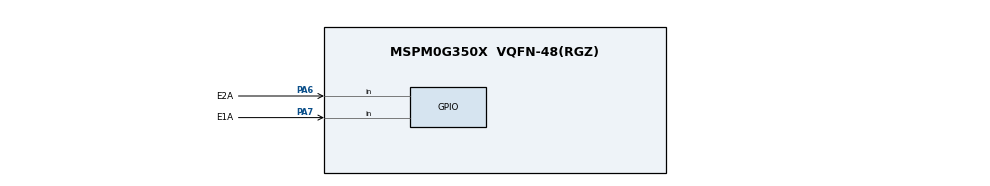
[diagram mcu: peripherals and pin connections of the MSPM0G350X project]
/**
 * @cliArgs --device "MSPM0G350X" --package "VQFN-48(RGZ)" --part "Default" --product "mspm0_sdk@2.00.01.00"
 * @versions {"tool":"1.20.0+3587"}
 */

/**
 * Import the modules used in this configuration.
 */
const Board  = scripting.addModule("/ti/driverlib/Board");
const GPIO   = scripting.addModule("/ti/driverlib/GPIO", {}, false);
const GPIO1  = GPIO.addInstance();
const GPIO2  = GPIO.addInstance();
const I2C    = scripting.addModule("/ti/driverlib/I2C", {}, false);
const I2C1   = I2C.addInstance();
const PWM    = scripting.addModule("/ti/driverlib/PWM", {}, false);
const PWM1   = PWM.addInstance();
const TIMER  = scripting.addModule("/ti/driverlib/TIMER", {}, false);
const TIMER1 = TIMER.addInstance();
const TIMER2 = TIMER.addInstance();

/**
 * Write custom configuration values to the imported modules.
 */

GPIO1.$name                       = "track";
GPIO1.associatedPins.create(8);
GPIO1.associatedPins[0].direction = "INPUT";
GPIO1.associatedPins[0].$name     = "PIN_1";
GPIO1.associatedPins[1].$name     = "PIN_2";
GPIO1.associatedPins[1].direction = "INPUT";
GPIO1.associatedPins[2].$name     = "PIN_3";
GPIO1.associatedPins[2].direction = "INPUT";
GPIO1.associatedPins[3].$name     = "PIN_4";
GPIO1.associatedPins[3].direction = "INPUT";
GPIO1.associatedPins[4].$name     = "PIN_5";
GPIO1.associatedPins[4].direction = "INPUT";
GPIO1.associatedPins[5].$name     = "PIN_6";
GPIO1.associatedPins[5].direction = "INPUT";
GPIO1.associatedPins[6].$name     = "PIN_7";
GPIO1.associatedPins[6].direction = "INPUT";
GPIO1.associatedPins[7].$name     = "PIN_8";
GPIO1.associatedPins[7].direction = "INPUT";

GPIO2.$name                         = "motor";
GPIO2.associatedPins.create(8);
GPIO2.associatedPins[0].$name       = "AIN1";
GPIO2.associatedPins[1].$name       = "AIN2";
GPIO2.associatedPins[2].$name       = "BIN1";
GPIO2.associatedPins[3].$name       = "BIN2";
GPIO2.associatedPins[4].$name       = "E1A";
GPIO2.associatedPins[4].direction   = "INPUT";
GPIO2.associatedPins[4].interruptEn = true;
GPIO2.associatedPins[4].polarity    = "FALL";
GPIO2.associatedPins[4].pin.$assign = "PA7";
GPIO2.associatedPins[5].$name       = "E2A";
GPIO2.associatedPins[5].direction   = "INPUT";
GPIO2.associatedPins[5].interruptEn = true;
GPIO2.associatedPins[5].polarity    = "FALL";
GPIO2.associatedPins[5].pin.$assign = "PA6";
GPIO2.associatedPins[6].$name       = "E1B";
GPIO2.associatedPins[6].direction   = "INPUT";
GPIO2.associatedPins[7].$name       = "E2B";
GPIO2.associatedPins[7].direction   = "INPUT";

I2C1.$name              = "I2C_0";
I2C1.sdaPinConfig.$name = "ti_driverlib_gpio_GPIOPinGeneric0";
I2C1.sclPinConfig.$name = "ti_driverlib_gpio_GPIOPinGeneric1";

PWM1.$name                              = "PWM_motor";
PWM1.timerStartTimer                    = true;
PWM1.clockPrescale                      = 256;
PWM1.timerCount                         = 125;
PWM1.PWM_CHANNEL_0.$name                = "ti_driverlib_pwm_PWMTimerCC0";
PWM1.PWM_CHANNEL_0.dutyCycle            = 50;
PWM1.PWM_CHANNEL_1.$name                = "ti_driverlib_pwm_PWMTimerCC1";
PWM1.PWM_CHANNEL_1.dutyCycle            = 25;
PWM1.ccp0PinConfig.$name                = "ti_driverlib_gpio_GPIOPinGeneric2";
PWM1.ccp0PinConfig.direction            = scripting.forceWrite("OUTPUT");
PWM1.ccp0PinConfig.hideOutputInversion  = scripting.forceWrite(false);
PWM1.ccp0PinConfig.onlyInternalResistor = scripting.forceWrite(false);
PWM1.ccp0PinConfig.passedPeripheralType = scripting.forceWrite("Digital");
PWM1.ccp1PinConfig.$name                = "ti_driverlib_gpio_GPIOPinGeneric3";
PWM1.ccp1PinConfig.direction            = scripting.forceWrite("OUTPUT");
PWM1.ccp1PinConfig.hideOutputInversion  = scripting.forceWrite(false);
PWM1.ccp1PinConfig.onlyInternalResistor = scripting.forceWrite(false);
PWM1.ccp1PinConfig.passedPeripheralType = scripting.forceWrite("Digital");

const SYSCTL = scripting.addModule("/ti/driverlib/SYSCTL", {}, false);

TIMER1.$name            = "TIMER_0";
TIMER1.timerClkPrescale = 256;
TIMER1.timerMode        = "PERIODIC";
TIMER1.timerPeriod      = "100ms";
TIMER1.interrupts       = ["ZERO"];

TIMER2.$name = "TIMER_1";

/**
 * Pinmux solution for unlocked pins/peripherals. This ensures that minor changes to the automatic solver in a future
 * version of the tool will not impact the pinmux you originally saw.  These lines can be completely deleted in order to
 * re-solve from scratch.
 */
Board.peripheral.$suggestSolution            = "DEBUGSS";
Board.peripheral.swclkPin.$suggestSolution   = "PA20";
Board.peripheral.swdioPin.$suggestSolution   = "PA19";
GPIO1.associatedPins[0].pin.$suggestSolution = "PA28";
GPIO1.associatedPins[1].pin.$suggestSolution = "PA31";
GPIO1.associatedPins[2].pin.$suggestSolution = "PA2";
GPIO1.associatedPins[3].pin.$suggestSolution = "PA3";
GPIO1.associatedPins[4].pin.$suggestSolution = "PA4";
GPIO1.associatedPins[5].pin.$suggestSolution = "PA5";
GPIO1.associatedPins[6].pin.$suggestSolution = "PB2";
GPIO1.associatedPins[7].pin.$suggestSolution = "PB3";
GPIO2.associatedPins[0].pin.$suggestSolution = "PA8";
GPIO2.associatedPins[1].pin.$suggestSolution = "PA9";
GPIO2.associatedPins[2].pin.$suggestSolution = "PA10";
GPIO2.associatedPins[3].pin.$suggestSolution = "PA11";
GPIO2.associatedPins[6].pin.$suggestSolution = "PB6";
GPIO2.associatedPins[7].pin.$suggestSolution = "PB7";
I2C1.peripheral.$suggestSolution             = "I2C0";
I2C1.peripheral.sdaPin.$suggestSolution      = "PA0";
I2C1.peripheral.sclPin.$suggestSolution      = "PA1";
PWM1.peripheral.$suggestSolution             = "TIMG0";
PWM1.peripheral.ccp0Pin.$suggestSolution     = "PA12";
PWM1.peripheral.ccp1Pin.$suggestSolution     = "PA13";
SYSCTL.peripheral.$suggestSolution           = "SYSCTL";
TIMER1.peripheral.$suggestSolution           = "TIMA1";
TIMER2.peripheral.$suggestSolution           = "TIMA0";
